# ATA6612C device description
Architecture: AVR8; Family: megaAVR
Programming and debug interfaces: ISP, HVPP, debugWIRE
Registers are 8-bit, access not given, no defined reset value unless marked. A register's access mark holds for its fields unless they carry their own. Offsets are from the block's base; lines under a group give offsets from that group; [hi:lo] are bit positions; {n}, {i} and the like mark numbered series; 'fields as' and 'values as' point back to an identical list; <NAME> marks a mode.

## Ordering variants
ATA6612C-PLQW-1: QFN48, up to 16 MHz, -40 to 125 C, 1.8 to 5.5 V

## Memory
prog space: start 0x0000 size 0x2000, little endian
  0x0000 FLASH size 0x2000 flash, rw, executable, page 0x40
  0x1f00 BOOT_SECTION_1 size 0x0100 flash, rw, executable, page 0x40
  0x1e00 BOOT_SECTION_2 size 0x0200 flash, rw, executable, page 0x40
  0x1c00 BOOT_SECTION_3 size 0x0400 flash, rw, executable, page 0x40
  0x1800 BOOT_SECTION_4 size 0x0800 flash, rw, executable, page 0x40
signatures space: start 0 size 3, little endian
  0 SIGNATURES size 3 signatures, ro
fuses space: start 0 size 0x0003, little endian
  0 FUSES size 0x0003 fuses, rw
lockbits space: start 0 size 0x0001, little endian
  0 LOCKBITS size 0x0001 lockbits, rw
data space: start 0x0000 size 0x0500, little endian
  0x0000 REGISTERS size 0x0020 regs
  0x0020 MAPPED_IO size 0x00e0 io
  0x0100 IRAM size 0x0400 ram
eeprom space: start 0x0000 size 0x0200, little endian
  0x0000 EEPROM size 0x0200 eeprom, rw, page 0x04
io space: start 0x00 size 0x40, little endian
osccal space: start 0 size 1, little endian
  0 OSCCAL size 1 osccal, ro

## Peripheral instances (address, pins/pin function, parameters)
USART0 at 0x00
TWI at 0x00
TIMER_COUNTER_1 at 0x00
TIMER_COUNTER_2 at 0x00
AD_CONVERTER at 0x00
ANALOG_COMPARATOR at 0x00
PORTB at 0x00
PORTC at 0x00
PORTD at 0x00
TIMER_COUNTER_0 at 0x00
EXTERNAL_INTERRUPT at 0x00
SPI at 0x00
CPU at 0x00
  parameters: CORE_VERSION=V2E
WDT at 0x00 — Watchdog Timer
EEPROM at 0x00
FUSE at 0 in fuses
LOCKBIT at 0 in lockbits

## Interrupts
0 RESET — External Pin, Power-on Reset, Brown-out Reset and Watchdog Reset
1 INT0 — External Interrupt Request 0
2 INT1 — External Interrupt Request 1
3 PCINT0 — Pin Change Interrupt Request 0
4 PCINT1 — Pin Change Interrupt Request 0
5 PCINT2 — Pin Change Interrupt Request 1
6 WDT — Watchdog Time-out Interrupt
7 TIMER2_COMPA — Timer/Counter2 Compare Match A
8 TIMER2_COMPB — Timer/Counter2 Compare Match A
9 TIMER2_OVF — Timer/Counter2 Overflow
10 TIMER1_CAPT — Timer/Counter1 Capture Event
11 TIMER1_COMPA — Timer/Counter1 Compare Match A
12 TIMER1_COMPB — Timer/Counter1 Compare Match B
13 TIMER1_OVF — Timer/Counter1 Overflow
14 TIMER0_COMPA — TimerCounter0 Compare Match A
15 TIMER0_COMPB — TimerCounter0 Compare Match B
16 TIMER0_OVF — Timer/Couner0 Overflow
17 SPI_STC — SPI Serial Transfer Complete
18 USART_RX — USART Rx Complete
19 USART_UDRE — USART, Data Register Empty
20 USART_TX — USART Tx Complete
21 ADC — ADC Conversion Complete
22 EE_READY — EEPROM Ready
23 ANALOG_COMP — Analog Comparator
24 TWI — Two-wire Serial Interface
25 SPM_Ready — Store Program Memory Read

## Properties
SIGNATURES: JTAGID=0x930A, SIGNATURE0=0x1e, SIGNATURE1=0x93, SIGNATURE2=0x0a
OCD: OCD_REVISION=1, OCD_DATAREG=0x31, PROGBASE=0x1000

## LOCKBIT
Instances: LOCKBIT 0 in lockbits
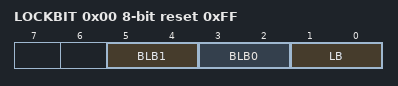
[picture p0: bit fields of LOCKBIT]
0x00 LOCKBIT reset 0xFF
  [5:4] BLB1 — Boot Loader Protection Mode
    0=LPM_SPM_DISABLE (LPM and SPM prohibited in Boot Section); 1=LPM_DISABLE (LPM prohibited in Boot Section); 2=SPM_DISABLE (SPM prohibited in Boot Section); 3=NO_LOCK (No lock on SPM and LPM in Boot Section)
  [3:2] BLB0 — Boot Loader Protection Mode
    0=LPM_SPM_DISABLE (LPM and SPM prohibited in Application Section); 1=LPM_DISABLE (LPM prohibited in Application Section); 2=SPM_DISABLE (SPM prohibited in Application Section); 3=NO_LOCK (No lock on SPM and LPM in Application Section)
  [1:0] LB — Memory Lock
    0=PROG_VER_DISABLED (Further programming and verification disabled); 2=PROG_DISABLED (Further programming disabled); 3=NO_LOCK (No memory lock features enabled)
